# Espressif register map
File version: 1.0
CPU: Xtensa LX6 1, little endian, no MPU, FPU, 3 interrupt priority bits
Registers are 32-bit, access not given, reset 0x0 unless marked. A register's access mark holds for its fields unless they carry their own. Offsets are from the block's base; [hi:lo] are bit positions; {n}, {i} and the like mark numbered series.

## RTCIO
Base 0x3FF48400
0x00 RTC_GPIO_OUT
  [31:14] RTC_GPIO_OUT_DATA
0x04 RTC_GPIO_OUT_W1TS
  [31:14] RTC_GPIO_OUT_DATA_W1TS
0x08 RTC_GPIO_OUT_W1TC
  [31:14] RTC_GPIO_OUT_DATA_W1TC
0x0C RTC_GPIO_ENABLE
  [31:14] RTC_GPIO_ENABLE
0x10 RTC_GPIO_ENABLE_W1TS
  [31:14] RTC_GPIO_ENABLE_W1TS
0x14 RTC_GPIO_ENABLE_W1TC
  [31:14] RTC_GPIO_ENABLE_W1TC
0x18 RTC_GPIO_STATUS
  [31:14] RTC_GPIO_STATUS_INT
0x1C RTC_GPIO_STATUS_W1TS
  [31:14] RTC_GPIO_STATUS_INT_W1TS
0x20 RTC_GPIO_STATUS_W1TC
  [31:14] RTC_GPIO_STATUS_INT_W1TC
0x24 RTC_GPIO_IN
  [31:14] RTC_GPIO_IN_NEXT
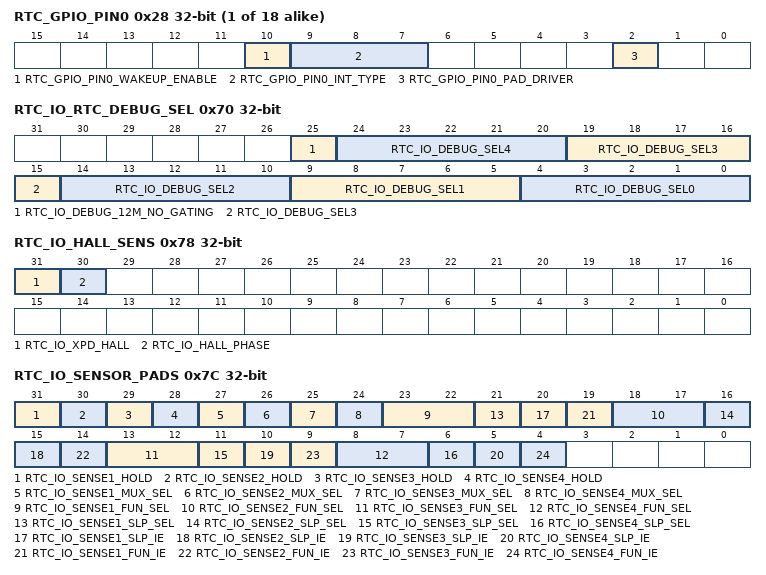
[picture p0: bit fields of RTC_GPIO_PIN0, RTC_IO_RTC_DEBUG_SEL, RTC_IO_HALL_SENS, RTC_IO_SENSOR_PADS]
{0x28+4i} RTC_GPIO_PIN{i} (i=0..17)
  [10] RTC_GPIO_PIN{i}_WAKEUP_ENABLE, [9:7] RTC_GPIO_PIN{i}_INT_TYPE, [2] RTC_GPIO_PIN{i}_PAD_DRIVER
0x70 RTC_IO_RTC_DEBUG_SEL
  [25] RTC_IO_DEBUG_12M_NO_GATING, [5n+4:5n] RTC_IO_DEBUG_SEL{n} (n=0..4)
0x74 RTC_IO_DIG_PAD_HOLD
0x78 RTC_IO_HALL_SENS
  [31] RTC_IO_XPD_HALL, [30] RTC_IO_HALL_PHASE
0x7C RTC_IO_SENSOR_PADS
  [32-n] RTC_IO_SENSE{n}_HOLD (n=1..4), [28-n] RTC_IO_SENSE{n}_MUX_SEL (n=1..4), [28-5n:27-5n] RTC_IO_SENSE{n}_FUN_SEL (n=1..4), [26-5n] RTC_IO_SENSE{n}_SLP_SEL (n=1..4), [25-5n] RTC_IO_SENSE{n}_SLP_IE (n=1..4), [24-5n] RTC_IO_SENSE{n}_FUN_IE (n=1..4)
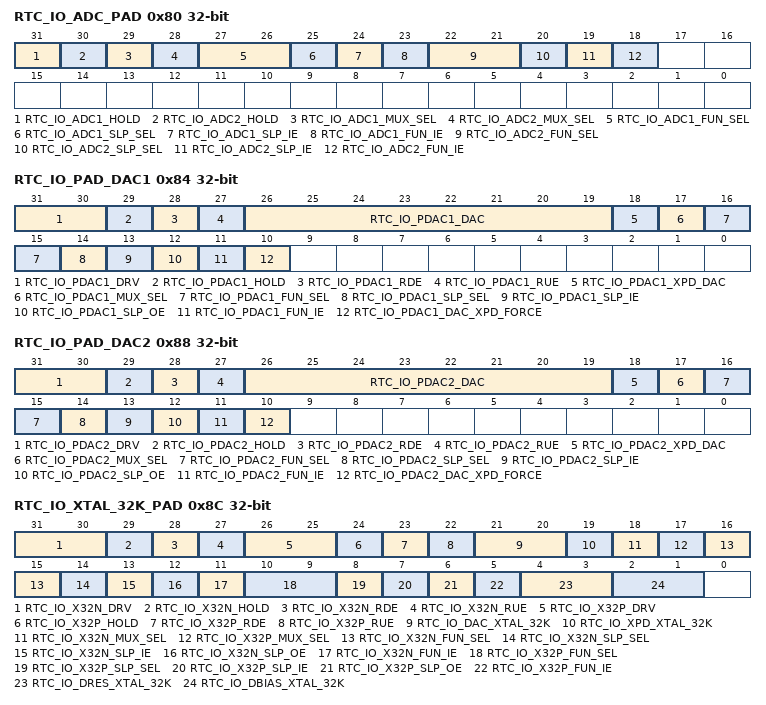
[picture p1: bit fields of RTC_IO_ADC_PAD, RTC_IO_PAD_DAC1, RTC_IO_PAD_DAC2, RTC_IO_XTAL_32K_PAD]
0x80 RTC_IO_ADC_PAD
  [31] RTC_IO_ADC1_HOLD, [30] RTC_IO_ADC2_HOLD, [29] RTC_IO_ADC1_MUX_SEL, [28] RTC_IO_ADC2_MUX_SEL, [27:26] RTC_IO_ADC1_FUN_SEL, [25] RTC_IO_ADC1_SLP_SEL, [24] RTC_IO_ADC1_SLP_IE, [23] RTC_IO_ADC1_FUN_IE, [22:21] RTC_IO_ADC2_FUN_SEL, [20] RTC_IO_ADC2_SLP_SEL, [19] RTC_IO_ADC2_SLP_IE, [18] RTC_IO_ADC2_FUN_IE
0x84 RTC_IO_PAD_DAC1
  [31:30] RTC_IO_PDAC1_DRV, [29] RTC_IO_PDAC1_HOLD, [28] RTC_IO_PDAC1_RDE, [27] RTC_IO_PDAC1_RUE, [26:19] RTC_IO_PDAC1_DAC, [18] RTC_IO_PDAC1_XPD_DAC, [17] RTC_IO_PDAC1_MUX_SEL, [16:15] RTC_IO_PDAC1_FUN_SEL, [14] RTC_IO_PDAC1_SLP_SEL, [13] RTC_IO_PDAC1_SLP_IE, [12] RTC_IO_PDAC1_SLP_OE, [11] RTC_IO_PDAC1_FUN_IE, [10] RTC_IO_PDAC1_DAC_XPD_FORCE
0x88 RTC_IO_PAD_DAC2
  [31:30] RTC_IO_PDAC2_DRV, [29] RTC_IO_PDAC2_HOLD, [28] RTC_IO_PDAC2_RDE, [27] RTC_IO_PDAC2_RUE, [26:19] RTC_IO_PDAC2_DAC, [18] RTC_IO_PDAC2_XPD_DAC, [17] RTC_IO_PDAC2_MUX_SEL, [16:15] RTC_IO_PDAC2_FUN_SEL, [14] RTC_IO_PDAC2_SLP_SEL, [13] RTC_IO_PDAC2_SLP_IE, [12] RTC_IO_PDAC2_SLP_OE, [11] RTC_IO_PDAC2_FUN_IE, [10] RTC_IO_PDAC2_DAC_XPD_FORCE
0x8C RTC_IO_XTAL_32K_PAD
  [31:30] RTC_IO_X32N_DRV, [29] RTC_IO_X32N_HOLD, [28] RTC_IO_X32N_RDE, [27] RTC_IO_X32N_RUE, [26:25] RTC_IO_X32P_DRV, [24] RTC_IO_X32P_HOLD, [23] RTC_IO_X32P_RDE, [22] RTC_IO_X32P_RUE, [21:20] RTC_IO_DAC_XTAL_32K, [19] RTC_IO_XPD_XTAL_32K, [18] RTC_IO_X32N_MUX_SEL, [17] RTC_IO_X32P_MUX_SEL, [16:15] RTC_IO_X32N_FUN_SEL, [14] RTC_IO_X32N_SLP_SEL, [13] RTC_IO_X32N_SLP_IE, [12] RTC_IO_X32N_SLP_OE, [11] RTC_IO_X32N_FUN_IE, [10:9] RTC_IO_X32P_FUN_SEL, [8] RTC_IO_X32P_SLP_SEL, [7] RTC_IO_X32P_SLP_IE, [6] RTC_IO_X32P_SLP_OE, [5] RTC_IO_X32P_FUN_IE, [4:3] RTC_IO_DRES_XTAL_32K, [2:1] RTC_IO_DBIAS_XTAL_32K
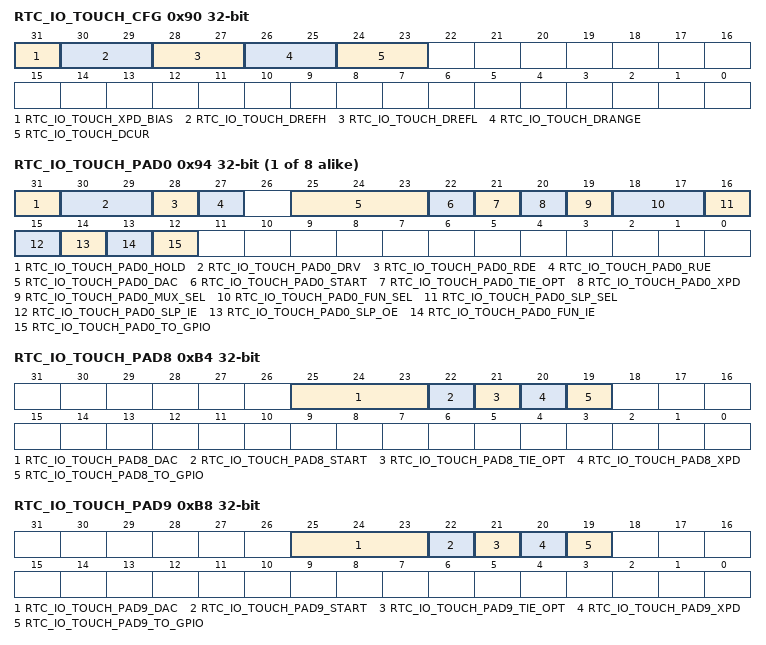
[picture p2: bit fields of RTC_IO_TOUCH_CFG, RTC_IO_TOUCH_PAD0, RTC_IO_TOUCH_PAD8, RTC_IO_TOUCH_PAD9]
0x90 RTC_IO_TOUCH_CFG
  [31] RTC_IO_TOUCH_XPD_BIAS, [30:29] RTC_IO_TOUCH_DREFH, [28:27] RTC_IO_TOUCH_DREFL, [26:25] RTC_IO_TOUCH_DRANGE, [24:23] RTC_IO_TOUCH_DCUR
{0x94+4i} RTC_IO_TOUCH_PAD{i} (i=0..7)
  [31] RTC_IO_TOUCH_PAD{i}_HOLD, [30:29] RTC_IO_TOUCH_PAD{i}_DRV, [28] RTC_IO_TOUCH_PAD{i}_RDE, [27] RTC_IO_TOUCH_PAD{i}_RUE, [25:23] RTC_IO_TOUCH_PAD{i}_DAC, [22] RTC_IO_TOUCH_PAD{i}_START, [21] RTC_IO_TOUCH_PAD{i}_TIE_OPT, [20] RTC_IO_TOUCH_PAD{i}_XPD, [19] RTC_IO_TOUCH_PAD{i}_MUX_SEL, [18:17] RTC_IO_TOUCH_PAD{i}_FUN_SEL, [16] RTC_IO_TOUCH_PAD{i}_SLP_SEL, [15] RTC_IO_TOUCH_PAD{i}_SLP_IE, [14] RTC_IO_TOUCH_PAD{i}_SLP_OE, [13] RTC_IO_TOUCH_PAD{i}_FUN_IE, [12] RTC_IO_TOUCH_PAD{i}_TO_GPIO
0xB4 RTC_IO_TOUCH_PAD8
  [25:23] RTC_IO_TOUCH_PAD8_DAC, [22] RTC_IO_TOUCH_PAD8_START, [21] RTC_IO_TOUCH_PAD8_TIE_OPT, [20] RTC_IO_TOUCH_PAD8_XPD, [19] RTC_IO_TOUCH_PAD8_TO_GPIO
0xB8 RTC_IO_TOUCH_PAD9
  [25:23] RTC_IO_TOUCH_PAD9_DAC, [22] RTC_IO_TOUCH_PAD9_START, [21] RTC_IO_TOUCH_PAD9_TIE_OPT, [20] RTC_IO_TOUCH_PAD9_XPD, [19] RTC_IO_TOUCH_PAD9_TO_GPIO
0xBC RTC_IO_EXT_WAKEUP0
  [31:27] RTC_IO_EXT_WAKEUP0_SEL
0xC0 RTC_IO_XTL_EXT_CTR
  [31:27] RTC_IO_XTL_EXT_CTR_SEL
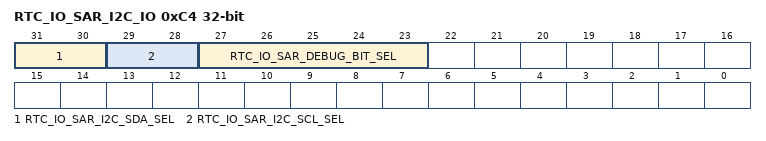
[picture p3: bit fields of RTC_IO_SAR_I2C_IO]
0xC4 RTC_IO_SAR_I2C_IO
  [31:30] RTC_IO_SAR_I2C_SDA_SEL, [29:28] RTC_IO_SAR_I2C_SCL_SEL, [27:23] RTC_IO_SAR_DEBUG_BIT_SEL
0xC8 RTC_IO_DATE
  [27:0] RTC_IO_IO_DATE
